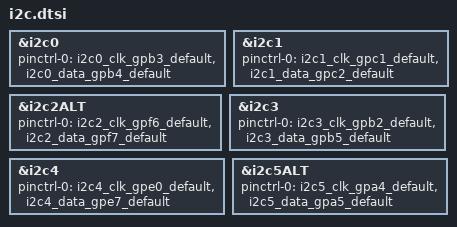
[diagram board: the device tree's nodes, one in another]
/* Copyright 2024 The ChromiumOS Authors
 * Use of this source code is governed by a BSD-style license that can be
 * found in the LICENSE file.
 */

 &i2c0 {
	status = "okay";
	pinctrl-0 = <&i2c0_clk_gpb3_default
		&i2c0_data_gpb4_default>;
	pinctrl-names = "default";
};

&i2c1 {
	status = "okay";
	pinctrl-0 = <&i2c1_clk_gpc1_default
		&i2c1_data_gpc2_default>;
	pinctrl-names = "default";
};

&i2c2ALT {
	status = "okay";
	pinctrl-0 = <&i2c2_clk_gpf6_default
		&i2c2_data_gpf7_default>;
	pinctrl-names = "default";
};

&i2c3 {
	status = "okay";
	pinctrl-0 = <&i2c3_clk_gpb2_default
		&i2c3_data_gpb5_default>;
	pinctrl-names = "default";
};

&i2c4 {
	status = "okay";
	pinctrl-0 = <&i2c4_clk_gpe0_default
		&i2c4_data_gpe7_default>;
	pinctrl-names = "default";
};

&i2c5ALT {
	status = "okay";
	pinctrl-0 = <&i2c5_clk_gpa4_default
		&i2c5_data_gpa5_default>;
	pinctrl-names = "default";
};
